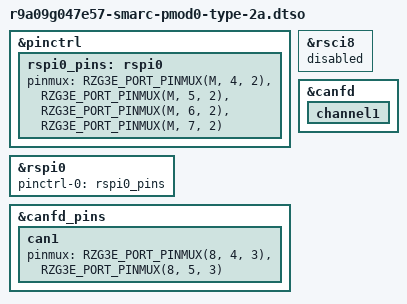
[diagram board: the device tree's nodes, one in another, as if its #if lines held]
// SPDX-License-Identifier: (GPL-2.0-only OR BSD-2-Clause)
/*
 * Device Tree Source for the RZ/G3E SMARC Carrier II EVK PMOD parts
 *
 * [Connection]
 *
 * SMARC Carrier II EVK
 * +-----------------------------------------+
 * | PMOD0_2A (PMOD PIN HEADER)              |
 * | SPI1_CS0#    (pin1)  (pin7) PMOD0_GPIO4 |
 * | SPI1_DO      (pin2)  (pin8) PMOD0_GPIO5 |
 * | SPI1_DIN     (pin3)  (pin9) PMOD0_GPIO6 |
 * | SPI1_CK      (pin4)  (pin10)PMOD0_GPIO7 |
 * | GND          (pin5)  (pin11)GND         |
 * | PWR_PMOD0    (pin6)  (pin12)PWR_PMOD0   |
 * +-----------------------------------------+
 *
 * Select the PMOD0 supply using PMOD_PWR_SEL.
 */

/dts-v1/;
/plugin/;

#include <dt-bindings/gpio/gpio.h>
#include <dt-bindings/pinctrl/renesas,r9a09g047-pinctrl.h>

#include "rzg3e-smarc-switches.h"

/* 0 = RSPI0, 1 = BSP RSCI8 SPI. */
#define RSPI0_RSCI8_SEL	0

/* Release GPIO6/7 with PMOD_GPIO6/7=1 in the base DTS before enabling CAN1. */
#define PMOD0_CAN1	SW_OFF

#if PMOD0_CAN1 && (SW_LCD_EN || SW_GPIO9_CAN1_STB)
#error "PMOD0 CAN1 requires SW_LCD_EN=0 and SW_GPIO9_CAN1_STB=0"
#endif

&pinctrl {
#if RSPI0_RSCI8_SEL
	rsci8_master_pins: rsci8-master {
		pinmux = <RZG3E_PORT_PINMUX(M, 5, 5)>, /* MOSI8 */
			 <RZG3E_PORT_PINMUX(M, 4, 5)>, /* MISO8 */
			 <RZG3E_PORT_PINMUX(M, 6, 5)>; /* SCK8 */
	};
#else
	rspi0_pins: rspi0 {
		pinmux = <RZG3E_PORT_PINMUX(M, 4, 2)>, /* MISOA */
			 <RZG3E_PORT_PINMUX(M, 5, 2)>, /* MOSIA */
			 <RZG3E_PORT_PINMUX(M, 6, 2)>, /* RSPCKA */
			 <RZG3E_PORT_PINMUX(M, 7, 2)>; /* SSLA0 */
	};
#endif
};

#if RSPI0_RSCI8_SEL
&rspi0 {
	status = "disabled";
};

&rsci8 {
	pinctrl-0 = <&rsci8_master_pins>;
	pinctrl-names = "master";
	status = "okay";

	renesas,rsci_spi;
	num-cs = <1>;
	#address-cells = <1>;
	#size-cells = <0>;
	cs-gpios = <&pinctrl RZG3E_GPIO(M, 7) GPIO_ACTIVE_HIGH>;
};
#else
&rspi0 {
	pinctrl-0 = <&rspi0_pins>;
	pinctrl-names = "default";
	status = "okay";
};

&rsci8 {
	status = "disabled";
};
#endif

#if PMOD0_CAN1
&canfd_pins {
	can1 {
		pinmux = <RZG3E_PORT_PINMUX(8, 4, 3)>, /* CRX1 */
			 <RZG3E_PORT_PINMUX(8, 5, 3)>; /* CTX1 */
	};
};

&canfd {
	channel1 {
		status = "okay";
	};
};
#endif
